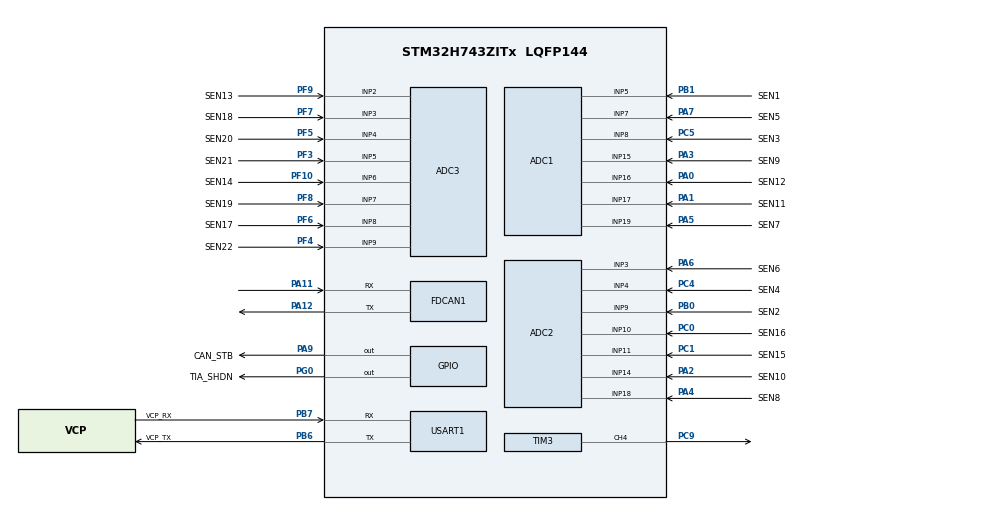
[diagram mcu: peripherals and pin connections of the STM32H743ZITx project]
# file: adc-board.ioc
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ADC1.Channel-0\#ChannelRegularConversion=ADC_CHANNEL_5
ADC1.Channel-1\#ChannelRegularConversion=ADC_CHANNEL_8
ADC1.Channel-2\#ChannelRegularConversion=ADC_CHANNEL_7
ADC1.Channel-3\#ChannelRegularConversion=ADC_CHANNEL_19
ADC1.Channel-4\#ChannelRegularConversion=ADC_CHANNEL_15
ADC1.Channel-5\#ChannelRegularConversion=ADC_CHANNEL_17
ADC1.Channel-6\#ChannelRegularConversion=ADC_CHANNEL_16
ADC1.ClockPrescaler=ADC_CLOCK_ASYNC_DIV1
ADC1.ContinuousConvMode=DISABLE
ADC1.ConversionDataManagement=ADC_CONVERSIONDATA_DMA_CIRCULAR
ADC1.DiscontinuousConvMode=ENABLE
ADC1.EOCSelection=ADC_EOC_SEQ_CONV
ADC1.ExternalTrigConv=ADC_EXTERNALTRIG_T3_TRGO
ADC1.Mode=ADC_MODE_INDEPENDENT
ADC1.NbrOfConversion=7
ADC1.NbrOfConversionFlag=1
ADC1.OffsetNumber-0\#ChannelRegularConversion=ADC_OFFSET_NONE
ADC1.OffsetNumber-1\#ChannelRegularConversion=ADC_OFFSET_NONE
ADC1.OffsetNumber-2\#ChannelRegularConversion=ADC_OFFSET_NONE
ADC1.OffsetNumber-3\#ChannelRegularConversion=ADC_OFFSET_NONE
ADC1.OffsetNumber-4\#ChannelRegularConversion=ADC_OFFSET_NONE
ADC1.OffsetNumber-5\#ChannelRegularConversion=ADC_OFFSET_NONE
ADC1.OffsetNumber-6\#ChannelRegularConversion=ADC_OFFSET_NONE
ADC1.OffsetSignedSaturation-0\#ChannelRegularConversion=DISABLE
ADC1.OffsetSignedSaturation-1\#ChannelRegularConversion=DISABLE
ADC1.OffsetSignedSaturation-2\#ChannelRegularConversion=DISABLE
ADC1.OffsetSignedSaturation-3\#ChannelRegularConversion=DISABLE
ADC1.OffsetSignedSaturation-4\#ChannelRegularConversion=DISABLE
ADC1.OffsetSignedSaturation-5\#ChannelRegularConversion=DISABLE
ADC1.OffsetSignedSaturation-6\#ChannelRegularConversion=DISABLE
ADC1.OversamplingMode=DISABLE
ADC1.Rank-0\#ChannelRegularConversion=1
ADC1.Rank-1\#ChannelRegularConversion=2
ADC1.Rank-2\#ChannelRegularConversion=3
ADC1.Rank-3\#ChannelRegularConversion=4
ADC1.Rank-4\#ChannelRegularConversion=5
ADC1.Rank-5\#ChannelRegularConversion=6
ADC1.Rank-6\#ChannelRegularConversion=7
ADC1.Ratio=1
ADC1.SamplingTime-0\#ChannelRegularConversion=ADC_SAMPLETIME_64CYCLES_5
ADC1.SamplingTime-1\#ChannelRegularConversion=ADC_SAMPLETIME_64CYCLES_5
ADC1.SamplingTime-2\#ChannelRegularConversion=ADC_SAMPLETIME_64CYCLES_5
ADC1.SamplingTime-3\#ChannelRegularConversion=ADC_SAMPLETIME_64CYCLES_5
ADC1.SamplingTime-4\#ChannelRegularConversion=ADC_SAMPLETIME_64CYCLES_5
ADC1.SamplingTime-5\#ChannelRegularConversion=ADC_SAMPLETIME_64CYCLES_5
ADC1.SamplingTime-6\#ChannelRegularConversion=ADC_SAMPLETIME_64CYCLES_5
ADC1.master=1
ADC2.Channel-0\#ChannelRegularConversion=ADC_CHANNEL_9
ADC2.Channel-1\#ChannelRegularConversion=ADC_CHANNEL_4
ADC2.Channel-2\#ChannelRegularConversion=ADC_CHANNEL_3
ADC2.Channel-3\#ChannelRegularConversion=ADC_CHANNEL_18
ADC2.Channel-4\#ChannelRegularConversion=ADC_CHANNEL_14
ADC2.Channel-5\#ChannelRegularConversion=ADC_CHANNEL_11
ADC2.Channel-6\#ChannelRegularConversion=ADC_CHANNEL_10
ADC2.ConversionDataManagement=ADC_CONVERSIONDATA_DMA_CIRCULAR
ADC2.DiscontinuousConvMode=ENABLE
ADC2.EOCSelection=ADC_EOC_SEQ_CONV
ADC2.ExternalTrigConv=ADC_EXTERNALTRIG_T3_CC4
ADC2.ExternalTrigConvEdge=ADC_EXTERNALTRIGCONVEDGE_RISINGFALLING
ADC2.NbrOfConversion=7
ADC2.NbrOfConversionFlag=1
ADC2.OffsetNumber-0\#ChannelRegularConversion=ADC_OFFSET_NONE
ADC2.OffsetNumber-1\#ChannelRegularConversion=ADC_OFFSET_NONE
ADC2.OffsetNumber-2\#ChannelRegularConversion=ADC_OFFSET_NONE
ADC2.OffsetNumber-3\#ChannelRegularConversion=ADC_OFFSET_NONE
ADC2.OffsetNumber-4\#ChannelRegularConversion=ADC_OFFSET_NONE
ADC2.OffsetNumber-5\#ChannelRegularConversion=ADC_OFFSET_NONE
ADC2.OffsetNumber-6\#ChannelRegularConversion=ADC_OFFSET_NONE
ADC2.OffsetSignedSaturation-0\#ChannelRegularConversion=DISABLE
ADC2.OffsetSignedSaturation-1\#ChannelRegularConversion=DISABLE
ADC2.OffsetSignedSaturation-2\#ChannelRegularConversion=DISABLE
ADC2.OffsetSignedSaturation-3\#ChannelRegularConversion=DISABLE
ADC2.OffsetSignedSaturation-4\#ChannelRegularConversion=DISABLE
ADC2.OffsetSignedSaturation-5\#ChannelRegularConversion=DISABLE
ADC2.OffsetSignedSaturation-6\#ChannelRegularConversion=DISABLE
ADC2.OversamplingMode=DISABLE
ADC2.Rank-0\#ChannelRegularConversion=1
ADC2.Rank-1\#ChannelRegularConversion=2
ADC2.Rank-2\#ChannelRegularConversion=3
ADC2.Rank-3\#ChannelRegularConversion=4
ADC2.Rank-4\#ChannelRegularConversion=5
ADC2.Rank-5\#ChannelRegularConversion=6
ADC2.Rank-6\#ChannelRegularConversion=7
ADC2.Ratio=1
ADC2.SamplingTime-0\#ChannelRegularConversion=ADC_SAMPLETIME_64CYCLES_5
ADC2.SamplingTime-1\#ChannelRegularConversion=ADC_SAMPLETIME_64CYCLES_5
ADC2.SamplingTime-2\#ChannelRegularConversion=ADC_SAMPLETIME_64CYCLES_5
ADC2.SamplingTime-3\#ChannelRegularConversion=ADC_SAMPLETIME_64CYCLES_5
ADC2.SamplingTime-4\#ChannelRegularConversion=ADC_SAMPLETIME_64CYCLES_5
ADC2.SamplingTime-5\#ChannelRegularConversion=ADC_SAMPLETIME_64CYCLES_5
ADC2.SamplingTime-6\#ChannelRegularConversion=ADC_SAMPLETIME_64CYCLES_5
ADC3.Channel-0\#ChannelRegularConversion=ADC_CHANNEL_2
ADC3.Channel-1\#ChannelRegularConversion=ADC_CHANNEL_6
ADC3.Channel-2\#ChannelRegularConversion=ADC_CHANNEL_8
ADC3.Channel-3\#ChannelRegularConversion=ADC_CHANNEL_3
ADC3.Channel-4\#ChannelRegularConversion=ADC_CHANNEL_7
ADC3.Channel-5\#ChannelRegularConversion=ADC_CHANNEL_4
ADC3.Channel-6\#ChannelRegularConversion=ADC_CHANNEL_5
ADC3.Channel-7\#ChannelRegularConversion=ADC_CHANNEL_9
ADC3.ClockPrescaler=ADC_CLOCK_ASYNC_DIV1
ADC3.ContinuousConvMode=DISABLE
ADC3.ConversionDataManagement=ADC_CONVERSIONDATA_DMA_CIRCULAR
ADC3.DiscontinuousConvMode=ENABLE
ADC3.EOCSelection=ADC_EOC_SEQ_CONV
ADC3.ExternalTrigConv=ADC_EXTERNALTRIG_T4_TRGO
ADC3.NbrOfConversion=8
ADC3.NbrOfConversionFlag=1
ADC3.OffsetNumber-0\#ChannelRegularConversion=ADC_OFFSET_NONE
ADC3.OffsetNumber-1\#ChannelRegularConversion=ADC_OFFSET_NONE
ADC3.OffsetNumber-2\#ChannelRegularConversion=ADC_OFFSET_NONE
ADC3.OffsetNumber-3\#ChannelRegularConversion=ADC_OFFSET_NONE
ADC3.OffsetNumber-4\#ChannelRegularConversion=ADC_OFFSET_NONE
ADC3.OffsetNumber-5\#ChannelRegularConversion=ADC_OFFSET_NONE
ADC3.OffsetNumber-6\#ChannelRegularConversion=ADC_OFFSET_NONE
ADC3.OffsetNumber-7\#ChannelRegularConversion=ADC_OFFSET_NONE
ADC3.OffsetSignedSaturation-0\#ChannelRegularConversion=DISABLE
ADC3.OffsetSignedSaturation-1\#ChannelRegularConversion=DISABLE
ADC3.OffsetSignedSaturation-2\#ChannelRegularConversion=DISABLE
ADC3.OffsetSignedSaturation-3\#ChannelRegularConversion=DISABLE
ADC3.OffsetSignedSaturation-4\#ChannelRegularConversion=DISABLE
ADC3.OffsetSignedSaturation-5\#ChannelRegularConversion=DISABLE
ADC3.OffsetSignedSaturation-6\#ChannelRegularConversion=DISABLE
ADC3.OffsetSignedSaturation-7\#ChannelRegularConversion=DISABLE
ADC3.OversamplingMode=DISABLE
ADC3.Rank-0\#ChannelRegularConversion=1
ADC3.Rank-1\#ChannelRegularConversion=2
ADC3.Rank-2\#ChannelRegularConversion=3
ADC3.Rank-3\#ChannelRegularConversion=4
ADC3.Rank-4\#ChannelRegularConversion=5
ADC3.Rank-5\#ChannelRegularConversion=6
ADC3.Rank-6\#ChannelRegularConversion=7
ADC3.Rank-7\#ChannelRegularConversion=8
ADC3.Ratio=1
ADC3.SamplingTime-0\#ChannelRegularConversion=ADC_SAMPLETIME_64CYCLES_5
ADC3.SamplingTime-1\#ChannelRegularConversion=ADC_SAMPLETIME_64CYCLES_5
ADC3.SamplingTime-2\#ChannelRegularConversion=ADC_SAMPLETIME_64CYCLES_5
ADC3.SamplingTime-3\#ChannelRegularConversion=ADC_SAMPLETIME_64CYCLES_5
ADC3.SamplingTime-4\#ChannelRegularConversion=ADC_SAMPLETIME_64CYCLES_5
ADC3.SamplingTime-5\#ChannelRegularConversion=ADC_SAMPLETIME_64CYCLES_5
ADC3.SamplingTime-6\#ChannelRegularConversion=ADC_SAMPLETIME_64CYCLES_5
ADC3.SamplingTime-7\#ChannelRegularConversion=ADC_SAMPLETIME_64CYCLES_5
Bdma.ADC3.0.Direction=DMA_PERIPH_TO_MEMORY
Bdma.ADC3.0.EventEnable=DISABLE
Bdma.ADC3.0.Instance=BDMA_Channel0
Bdma.ADC3.0.MemDataAlignment=DMA_MDATAALIGN_HALFWORD
Bdma.ADC3.0.MemInc=DMA_MINC_ENABLE
Bdma.ADC3.0.Mode=DMA_CIRCULAR
Bdma.ADC3.0.PeriphDataAlignment=DMA_PDATAALIGN_HALFWORD
Bdma.ADC3.0.PeriphInc=DMA_PINC_DISABLE
Bdma.ADC3.0.Polarity=HAL_DMAMUX_REQ_GEN_RISING
Bdma.ADC3.0.Priority=DMA_PRIORITY_LOW
Bdma.ADC3.0.RequestNumber=1
Bdma.ADC3.0.SignalID=NONE
Bdma.ADC3.0.SyncEnable=DISABLE
Bdma.ADC3.0.SyncPolarity=HAL_DMAMUX_SYNC_NO_EVENT
Bdma.ADC3.0.SyncRequestNumber=1
Bdma.ADC3.0.SyncSignalID=NONE
Bdma.Request0=ADC3
Bdma.RequestsNb=1
CORTEX_M7.default_mode_Activation=1
Dma.ADC1.0.Direction=DMA_PERIPH_TO_MEMORY
Dma.ADC1.0.EventEnable=DISABLE
Dma.ADC1.0.FIFOMode=DMA_FIFOMODE_DISABLE
Dma.ADC1.0.Instance=DMA1_Stream0
Dma.ADC1.0.MemDataAlignment=DMA_MDATAALIGN_HALFWORD
Dma.ADC1.0.MemInc=DMA_MINC_ENABLE
Dma.ADC1.0.Mode=DMA_CIRCULAR
Dma.ADC1.0.PeriphDataAlignment=DMA_PDATAALIGN_HALFWORD
Dma.ADC1.0.PeriphInc=DMA_PINC_DISABLE
Dma.ADC1.0.Polarity=HAL_DMAMUX_REQ_GEN_RISING
Dma.ADC1.0.Priority=DMA_PRIORITY_LOW
Dma.ADC1.0.RequestNumber=1
Dma.ADC1.0.SignalID=NONE
Dma.ADC1.0.SyncEnable=DISABLE
Dma.ADC1.0.SyncPolarity=HAL_DMAMUX_SYNC_NO_EVENT
Dma.ADC1.0.SyncRequestNumber=1
Dma.ADC1.0.SyncSignalID=NONE
Dma.ADC2.3.Direction=DMA_PERIPH_TO_MEMORY
Dma.ADC2.3.EventEnable=DISABLE
Dma.ADC2.3.FIFOMode=DMA_FIFOMODE_DISABLE
Dma.ADC2.3.Instance=DMA1_Stream3
Dma.ADC2.3.MemDataAlignment=DMA_MDATAALIGN_HALFWORD
Dma.ADC2.3.MemInc=DMA_MINC_ENABLE
Dma.ADC2.3.Mode=DMA_CIRCULAR
Dma.ADC2.3.PeriphDataAlignment=DMA_PDATAALIGN_HALFWORD
Dma.ADC2.3.PeriphInc=DMA_PINC_DISABLE
Dma.ADC2.3.Polarity=HAL_DMAMUX_REQ_GEN_RISING
Dma.ADC2.3.Priority=DMA_PRIORITY_LOW
Dma.ADC2.3.RequestNumber=1
Dma.ADC2.3.SignalID=NONE
Dma.ADC2.3.SyncEnable=DISABLE
Dma.ADC2.3.SyncPolarity=HAL_DMAMUX_SYNC_NO_EVENT
Dma.ADC2.3.SyncRequestNumber=1
Dma.ADC2.3.SyncSignalID=NONE
Dma.Request0=ADC1
Dma.Request1=USART1_RX
Dma.Request2=USART1_TX
Dma.Request3=ADC2
Dma.USART1_RX.1.Direction=DMA_PERIPH_TO_MEMORY
Dma.USART1_RX.1.EventEnable=DISABLE
Dma.USART1_RX.1.FIFOMode=DMA_FIFOMODE_DISABLE
Dma.USART1_RX.1.Instance=DMA1_Stream1
Dma.USART1_RX.1.MemDataAlignment=DMA_MDATAALIGN_BYTE
Dma.USART1_RX.1.MemInc=DMA_MINC_ENABLE
Dma.USART1_RX.1.Mode=DMA_CIRCULAR
Dma.USART1_RX.1.PeriphDataAlignment=DMA_PDATAALIGN_BYTE
Dma.USART1_RX.1.PeriphInc=DMA_PINC_DISABLE
Dma.USART1_RX.1.Polarity=HAL_DMAMUX_REQ_GEN_RISING
Dma.USART1_RX.1.Priority=DMA_PRIORITY_LOW
Dma.USART1_RX.1.RequestNumber=1
Dma.USART1_RX.1.SignalID=NONE
Dma.USART1_RX.1.SyncEnable=DISABLE
Dma.USART1_RX.1.SyncPolarity=HAL_DMAMUX_SYNC_NO_EVENT
Dma.USART1_RX.1.SyncRequestNumber=1
Dma.USART1_RX.1.SyncSignalID=NONE
Dma.USART1_TX.2.Direction=DMA_MEMORY_TO_PERIPH
Dma.USART1_TX.2.EventEnable=DISABLE
Dma.USART1_TX.2.FIFOMode=DMA_FIFOMODE_DISABLE
Dma.USART1_TX.2.Instance=DMA1_Stream2
Dma.USART1_TX.2.MemDataAlignment=DMA_MDATAALIGN_BYTE
Dma.USART1_TX.2.MemInc=DMA_MINC_ENABLE
Dma.USART1_TX.2.Mode=DMA_NORMAL
Dma.USART1_TX.2.PeriphDataAlignment=DMA_PDATAALIGN_BYTE
Dma.USART1_TX.2.PeriphInc=DMA_PINC_DISABLE
Dma.USART1_TX.2.Polarity=HAL_DMAMUX_REQ_GEN_RISING
Dma.USART1_TX.2.Priority=DMA_PRIORITY_LOW
Dma.USART1_TX.2.RequestNumber=1
Dma.USART1_TX.2.SignalID=NONE
Dma.USART1_TX.2.SyncEnable=DISABLE
Dma.USART1_TX.2.SyncPolarity=HAL_DMAMUX_SYNC_NO_EVENT
Dma.USART1_TX.2.SyncRequestNumber=1
Dma.USART1_TX.2.SyncSignalID=NONE
FDCAN1.CalculateBaudRateNominal=500000
FDCAN1.CalculateTimeBitNominal=2000
FDCAN1.CalculateTimeQuantumNominal=125.0
FDCAN1.FrameFormat=FDCAN_FRAME_FD_NO_BRS
FDCAN1.NominalPrescaler=10
FDCAN1.NominalTimeSeg1=12
FDCAN1.NominalTimeSeg2=3
FDCAN1.RxFifo0ElmtSize=FDCAN_DATA_BYTES_64
FDCAN1.RxFifo0ElmtsNbr=32
FDCAN1.StdFiltersNbr=5
FDCAN1.TxElmtSize=FDCAN_DATA_BYTES_64
FDCAN1.TxFifoQueueElmtsNbr=32
FREERTOS.Tasks01=defaultTask,24,1024,StartDefaultTask,Default,NULL,Dynamic,NULL,NULL
FREERTOS.configENABLE_FPU=1
FREERTOS.configGENERATE_RUN_TIME_STATS=1
FREERTOS.configTOTAL_HEAP_SIZE=32768
Mcu.Family=STM32H7
Mcu.Name=STM32H743ZITx
Mcu.Package=LQFP144
NVIC.BDMA_Channel0_IRQn=true\:5\:0\:false\:false\:true\:true\:false\:true\:true
NVIC.DMA1_Stream0_IRQn=true\:5\:0\:false\:false\:true\:true\:false\:true\:true
NVIC.DMA1_Stream1_IRQn=true\:5\:0\:false\:false\:true\:true\:false\:true\:true
NVIC.DMA1_Stream2_IRQn=true\:5\:0\:false\:false\:true\:true\:false\:true\:true
NVIC.DMA1_Stream3_IRQn=true\:5\:0\:false\:false\:true\:true\:false\:true\:true
NVIC.FDCAN1_IT0_IRQn=true\:5\:0\:false\:false\:true\:true\:true\:true\:true
NVIC.FDCAN1_IT1_IRQn=true\:5\:0\:false\:false\:true\:true\:true\:true\:true
NVIC.PriorityGroup=NVIC_PRIORITYGROUP_4
NVIC.TIM5_IRQn=true\:15\:0\:false\:false\:true\:false\:false\:true\:true
NVIC.TimeBase=TIM5_IRQn
NVIC.TimeBaseIP=TIM5
NVIC.USART1_IRQn=true\:5\:0\:false\:false\:true\:true\:true\:true\:true
PA0.GPIO_Label=SEN12
PA0.Mode=IN16-Single-Ended
PA0.Signal=ADC1_INP16
PA1.GPIO_Label=SEN11
PA1.Mode=IN17-Single-Ended
PA1.Signal=ADC1_INP17
PA11.Mode=FDCAN_Activate
PA11.Signal=FDCAN1_RX
PA12.Mode=FDCAN_Activate
PA12.Signal=FDCAN1_TX
PA13\ (JTMS/SWDIO).Mode=Serial_Wire
PA13\ (JTMS/SWDIO).Signal=DEBUG_JTMS-SWDIO
PA14\ (JTCK/SWCLK).Mode=Serial_Wire
PA14\ (JTCK/SWCLK).Signal=DEBUG_JTCK-SWCLK
PA2.GPIO_Label=SEN10
PA2.Signal=ADCx_INP14
PA3.GPIO_Label=SEN9
PA3.Signal=ADCx_INP15
PA4.GPIO_Label=SEN8
PA4.Signal=ADCx_INP18
PA5.GPIO_Label=SEN7
PA5.Signal=ADCx_INP19
PA6.GPIO_Label=SEN6
PA6.Signal=ADCx_INP3
PA7.GPIO_Label=SEN5
PA7.Signal=ADCx_INP7
PA9.GPIO_Label=CAN_STB
PA9.Signal=GPIO_Output
PB0.GPIO_Label=SEN2
PB0.Signal=ADCx_INP9
PB1.GPIO_Label=SEN1
PB1.Signal=ADCx_INP5
PB13.Signal=USB_OTG_HS_VBUS
PB14.Signal=USB_OTG_HS_DM
PB15.Signal=USB_OTG_HS_DP
PB6.GPIO_Label=VCP_TX
PB6.Mode=Asynchronous
PB6.Signal=USART1_TX
PB7.GPIO_Label=VCP_RX
PB7.Mode=Asynchronous
PB7.Signal=USART1_RX
PC0.GPIO_Label=SEN16
PC0.Signal=ADCx_INP10
PC1.GPIO_Label=SEN15
PC1.Signal=ADCx_INP11
PC4.GPIO_Label=SEN4
PC4.Signal=ADCx_INP4
PC5.GPIO_Label=SEN3
PC5.Signal=ADCx_INP8
PC9.Signal=S_TIM3_CH4
PD5.Signal=USART2_TX
PD6.Signal=USART2_RX
PD8.Signal=USART3_TX
PD9.Signal=USART3_RX
PF10.GPIO_Label=SEN14
PF10.Mode=IN6-Single-Ended
PF10.Signal=ADC3_INP6
PF3.GPIO_Label=SEN21
PF3.Mode=IN5-Single-Ended
PF3.Signal=ADC3_INP5
PF4.GPIO_Label=SEN22
PF4.Mode=IN9-Single-Ended
PF4.Signal=ADC3_INP9
PF5.GPIO_Label=SEN20
PF5.Mode=IN4-Single-Ended
PF5.Signal=ADC3_INP4
PF6.GPIO_Label=SEN17
PF6.Mode=IN8-Single-Ended
PF6.Signal=ADC3_INP8
PF7.GPIO_Label=SEN18
PF7.Mode=IN3-Single-Ended
PF7.Signal=ADC3_INP3
PF8.GPIO_Label=SEN19
PF8.Mode=IN7-Single-Ended
PF8.Signal=ADC3_INP7
PF9.GPIO_Label=SEN13
PF9.Mode=IN2-Single-Ended
PF9.Signal=ADC3_INP2
PG0.GPIO_Label=TIA_SHDN
PG0.Signal=GPIO_Output
PH0-OSC_IN\ (PH0).Mode=HSE-External-Oscillator
PH0-OSC_IN\ (PH0).Signal=RCC_OSC_IN
PH1-OSC_OUT\ (PH1).Mode=HSE-External-Oscillator
PH1-OSC_OUT\ (PH1).Signal=RCC_OSC_OUT
ProjectManager.HeapSize=0x200
ProjectManager.StackSize=0x400
ProjectManager.TargetToolchain=CMake
RCC.ADCFreq_Value=11428571.42857143
RCC.APB1Freq_Value=120000000
RCC.APB2Freq_Value=120000000
RCC.APB3Freq_Value=120000000
RCC.APB4Freq_Value=120000000
RCC.CortexFreq_Value=480000000
RCC.D1PPRE=RCC_APB3_DIV2
RCC.D2PPRE1=RCC_APB1_DIV2
RCC.D2PPRE2=RCC_APB2_DIV2
RCC.D3PPRE=RCC_APB4_DIV2
RCC.DIVM1=4
RCC.DIVM2=4
RCC.DIVN1=60
RCC.DIVN2=10
RCC.DIVP2=14
RCC.DIVQ1=12
RCC.HCLKFreq_Value=240000000
RCC.HPRE=RCC_HCLK_DIV2
RCC.HSE_VALUE=16000000
RCC.PLL2FRACN=0
RCC.PLLFRACN=0
RCC.SYSCLKFreq_VALUE=480000000
RCC.SYSCLKSource=RCC_SYSCLKSOURCE_PLLCLK
RCC.USBFreq_Value=80000000
SH.ADCx_INP10.0=ADC2_INP10,IN10-Single-Ended
SH.ADCx_INP11.0=ADC2_INP11,IN11-Single-Ended
SH.ADCx_INP14.0=ADC2_INP14,IN14-Single-Ended
SH.ADCx_INP15.0=ADC1_INP15,IN15-Single-Ended
SH.ADCx_INP18.0=ADC2_INP18,IN18-Single-Ended
SH.ADCx_INP19.0=ADC1_INP19,IN19-Single-Ended
SH.ADCx_INP3.0=ADC2_INP3,IN3-Single-Ended
SH.ADCx_INP4.0=ADC2_INP4,IN4-Single-Ended
SH.ADCx_INP5.0=ADC1_INP5,IN5-Single-Ended
SH.ADCx_INP7.0=ADC1_INP7,IN7-Single-Ended
SH.ADCx_INP8.0=ADC1_INP8,IN8-Single-Ended
SH.ADCx_INP9.0=ADC2_INP9,IN9-Single-Ended
SH.S_TIM3_CH4.0=TIM3_CH4,PWM Generation4 CH4
STMicroelectronics.X-CUBE-ALGOBUILD.1.4.0.LibraryCcDSPOoLibraryJjDSPOoLibrary=true
TIM2.ClockDivision=TIM_CLOCKDIVISION_DIV1
TIM2.Prescaler=239
TIM3.Channel-PWM\ Generation4\ CH4=TIM_CHANNEL_4
TIM3.Period=142
TIM3.Prescaler=239
TIM3.Pulse-PWM\ Generation4\ CH4=71
TIM3.TIM_MasterOutputTrigger=TIM_TRGO_UPDATE
TIM4.Period=124
TIM4.Prescaler=239
TIM4.TIM_MasterOutputTrigger=TIM_TRGO_UPDATE
USART1.VirtualMode-Asynchronous=VM_ASYNC
VP_FREERTOS_VS_CMSIS_V2.Mode=CMSIS_V2
VP_MEMORYMAP_VS_MEMORYMAP.Mode=CurAppReg
VP_STMicroelectronics.X-CUBE-ALGOBUILD_VS_DSPOoLibraryJjLibrary_1.4.0_1.4.0.Mode=DSPOoLibraryJjLibrary
VP_SYS_VS_tim5.Mode=TIM5
VP_TIM2_VS_ClockSourceINT.Mode=Internal
VP_TIM3_VS_ClockSourceINT.Mode=Internal
VP_TIM4_VS_ClockSourceINT.Mode=Internal
board=custom

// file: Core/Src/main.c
/* USER CODE BEGIN Header */
/**
  ******************************************************************************
  * @file           : main.c
  * @brief          : Main program body
  ******************************************************************************
  * @attention
  *
  * Copyright (c) 2026 STMicroelectronics.
  * All rights reserved.
  *
  * This software is licensed under terms that can be found in the LICENSE file
  * in the root directory of this software component.
  * If no LICENSE file comes with this software, it is provided AS-IS.
  *
  ******************************************************************************
  */
/* USER CODE END Header */
#include "main.h"
#include "cmsis_os.h"
#include "adc.h"
#include "bdma.h"
#include "dma.h"
#include "fdcan.h"
#include "tim.h"
#include "usart.h"
#include "gpio.h"

/* USER CODE BEGIN Includes */
#include "app/app_entry.h"
/* USER CODE END Includes */

void SystemClock_Config(void);
void PeriphCommonClock_Config(void);
static void MPU_Config(void);
void MX_FREERTOS_Init(void);

int main(void)
{

  /* USER CODE BEGIN 1 */
  SCB->VTOR = MIDISMITH_APPLICATION_LOAD_ADDRESS;
  __DSB();
  __ISB();
  /* USER CODE END 1 */

  /* MPU Configuration--------------------------------------------------------*/
  MPU_Config();

  /* MCU Configuration--------------------------------------------------------*/

  /* Reset of all peripherals, Initializes the Flash interface and the Systick. */
  HAL_Init();

  /* Configure the system clock */
  SystemClock_Config();

  /* Configure the peripherals common clocks */
  PeriphCommonClock_Config();

  /* Initialize all configured peripherals */
  MX_GPIO_Init();
  MX_DMA_Init();
  MX_BDMA_Init();
  MX_ADC1_Init();
  MX_ADC2_Init();
  MX_FDCAN1_Init();
  MX_ADC3_Init();
  MX_USART1_UART_Init();
  MX_TIM2_Init();
  MX_TIM3_Init();
  MX_TIM4_Init();
  /* USER CODE BEGIN 2 */
  AppEntry_Init();
  /* USER CODE END 2 */

  /* Init scheduler */
  osKernelInitialize();  /* Call init function for freertos objects (in cmsis_os2.c) */
  MX_FREERTOS_Init();

  /* Start scheduler */
  osKernelStart();

  /* We should never get here as control is now taken by the scheduler */

  /* Infinite loop */
  while (1)
  {

  }
}

void SystemClock_Config(void)
{
  RCC_OscInitTypeDef RCC_OscInitStruct = {0};
  RCC_ClkInitTypeDef RCC_ClkInitStruct = {0};

  /** Supply configuration update enable
  */
  HAL_PWREx_ConfigSupply(PWR_LDO_SUPPLY);

  /** Configure the main internal regulator output voltage
  */
  __HAL_PWR_VOLTAGESCALING_CONFIG(PWR_REGULATOR_VOLTAGE_SCALE0);

  while(!__HAL_PWR_GET_FLAG(PWR_FLAG_VOSRDY)) {}

  /** Initializes the RCC Oscillators according to the specified parameters
  * in the RCC_OscInitTypeDef structure.
  */
  RCC_OscInitStruct.OscillatorType = RCC_OSCILLATORTYPE_HSI;
  RCC_OscInitStruct.HSIState = RCC_HSI_DIV1;
  RCC_OscInitStruct.HSICalibrationValue = RCC_HSICALIBRATION_DEFAULT;
  RCC_OscInitStruct.PLL.PLLState = RCC_PLL_ON;
  RCC_OscInitStruct.PLL.PLLSource = RCC_PLLSOURCE_HSI;
  RCC_OscInitStruct.PLL.PLLM = 4;
  RCC_OscInitStruct.PLL.PLLN = 60;
  RCC_OscInitStruct.PLL.PLLP = 2;
  RCC_OscInitStruct.PLL.PLLQ = 12;
  RCC_OscInitStruct.PLL.PLLR = 2;
  RCC_OscInitStruct.PLL.PLLRGE = RCC_PLL1VCIRANGE_3;
  RCC_OscInitStruct.PLL.PLLVCOSEL = RCC_PLL1VCOWIDE;
  RCC_OscInitStruct.PLL.PLLFRACN = 0;
  if (HAL_RCC_OscConfig(&RCC_OscInitStruct) != HAL_OK)
  {
    Error_Handler();
  }

  /** Initializes the CPU, AHB and APB buses clocks
  */
  RCC_ClkInitStruct.ClockType = RCC_CLOCKTYPE_HCLK|RCC_CLOCKTYPE_SYSCLK
                              |RCC_CLOCKTYPE_PCLK1|RCC_CLOCKTYPE_PCLK2
                              |RCC_CLOCKTYPE_D3PCLK1|RCC_CLOCKTYPE_D1PCLK1;
  RCC_ClkInitStruct.SYSCLKSource = RCC_SYSCLKSOURCE_PLLCLK;
  RCC_ClkInitStruct.SYSCLKDivider = RCC_SYSCLK_DIV1;
  RCC_ClkInitStruct.AHBCLKDivider = RCC_HCLK_DIV2;
  RCC_ClkInitStruct.APB3CLKDivider = RCC_APB3_DIV2;
  RCC_ClkInitStruct.APB1CLKDivider = RCC_APB1_DIV2;
  RCC_ClkInitStruct.APB2CLKDivider = RCC_APB2_DIV2;
  RCC_ClkInitStruct.APB4CLKDivider = RCC_APB4_DIV2;

  if (HAL_RCC_ClockConfig(&RCC_ClkInitStruct, FLASH_LATENCY_4) != HAL_OK)
  {
    Error_Handler();
  }
}

void PeriphCommonClock_Config(void)
{
  RCC_PeriphCLKInitTypeDef PeriphClkInitStruct = {0};

  /** Initializes the peripherals clock
  */
  PeriphClkInitStruct.PeriphClockSelection = RCC_PERIPHCLK_ADC;
  PeriphClkInitStruct.PLL2.PLL2M = 4;
  PeriphClkInitStruct.PLL2.PLL2N = 10;
  PeriphClkInitStruct.PLL2.PLL2P = 14;
  PeriphClkInitStruct.PLL2.PLL2Q = 2;
  PeriphClkInitStruct.PLL2.PLL2R = 2;
  PeriphClkInitStruct.PLL2.PLL2RGE = RCC_PLL2VCIRANGE_3;
  PeriphClkInitStruct.PLL2.PLL2VCOSEL = RCC_PLL2VCOMEDIUM;
  PeriphClkInitStruct.PLL2.PLL2FRACN = 0;
  PeriphClkInitStruct.AdcClockSelection = RCC_ADCCLKSOURCE_PLL2;
  if (HAL_RCCEx_PeriphCLKConfig(&PeriphClkInitStruct) != HAL_OK)
  {
    Error_Handler();
  }
}

 /* MPU Configuration */

void MPU_Config(void)
{
  MPU_Region_InitTypeDef MPU_InitStruct = {0};

  /* Disables the MPU */
  HAL_MPU_Disable();

  /** Initializes and configures the Region and the memory to be protected
  */
  MPU_InitStruct.Enable = MPU_REGION_ENABLE;
  MPU_InitStruct.Number = MPU_REGION_NUMBER0;
  MPU_InitStruct.BaseAddress = 0x0;
  MPU_InitStruct.Size = MPU_REGION_SIZE_4GB;
  MPU_InitStruct.SubRegionDisable = 0x87;
  MPU_InitStruct.TypeExtField = MPU_TEX_LEVEL0;
  MPU_InitStruct.AccessPermission = MPU_REGION_NO_ACCESS;
  MPU_InitStruct.DisableExec = MPU_INSTRUCTION_ACCESS_DISABLE;
  MPU_InitStruct.IsShareable = MPU_ACCESS_SHAREABLE;
  MPU_InitStruct.IsCacheable = MPU_ACCESS_NOT_CACHEABLE;
  MPU_InitStruct.IsBufferable = MPU_ACCESS_NOT_BUFFERABLE;

  HAL_MPU_ConfigRegion(&MPU_InitStruct);
  /* Enables the MPU */
  HAL_MPU_Enable(MPU_PRIVILEGED_DEFAULT);

}

void HAL_TIM_PeriodElapsedCallback(TIM_HandleTypeDef *htim)
{
  if (htim->Instance == TIM5)
  {
    HAL_IncTick();
  }
}

void Error_Handler(void)
{
  __disable_irq();
  while (1)
  {
  }
}
